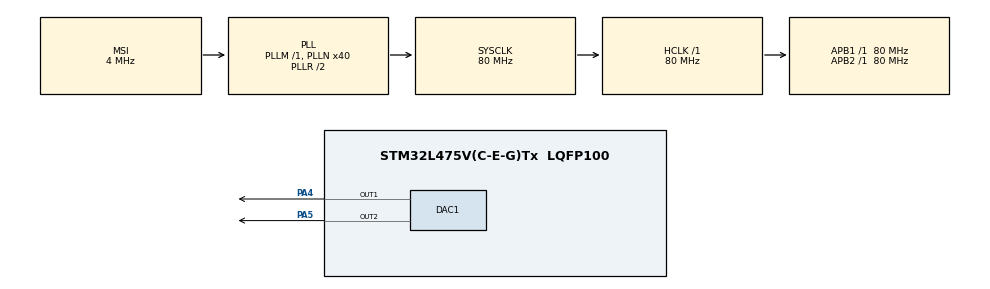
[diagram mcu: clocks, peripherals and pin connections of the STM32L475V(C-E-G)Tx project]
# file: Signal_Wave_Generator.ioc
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DAC1.DAC_Channel-DAC_OUT2=DAC_CHANNEL_2
Mcu.Family=STM32L4
Mcu.Name=STM32L475V(C-E-G)Tx
Mcu.Package=LQFP100
NVIC.PriorityGroup=NVIC_PRIORITYGROUP_4
PA13\ (JTMS-SWDIO).Signal=SYS_JTMS-SWDIO
PA4.Signal=COMP_DAC11_group
PA5.Signal=COMP_DAC12_group
PB3\ (JTDO-TRACESWO).Signal=SYS_JTDO-SWO
ProjectManager.HeapSize=0x200
ProjectManager.StackSize=0x400
ProjectManager.TargetToolchain=STM32CubeIDE
RCC.ADCFreq_Value=48000000
RCC.AHBFreq_Value=80000000
RCC.APB1Freq_Value=80000000
RCC.APB1TimFreq_Value=80000000
RCC.APB2Freq_Value=80000000
RCC.APB2TimFreq_Value=80000000
RCC.CortexFreq_Value=80000000
RCC.HCLKFreq_Value=80000000
RCC.HSE_VALUE=8000000
RCC.HSI_VALUE=16000000
RCC.MSI_VALUE=4000000
RCC.PLLN=40
RCC.PLLSAI1N=24
RCC.SYSCLKFreq_VALUE=80000000
RCC.SYSCLKSource=RCC_SYSCLKSOURCE_PLLCLK
RCC.USBFreq_Value=48000000
RCC.VCOOutputFreq_Value=160000000
SH.COMP_DAC11_group.0=DAC1_OUT1,DAC_OUT1
SH.COMP_DAC12_group.0=DAC1_OUT2,DAC_OUT2
board=B-L475E-IOT01A1

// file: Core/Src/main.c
/* USER CODE BEGIN Header */
/**
  ******************************************************************************
  * @file           : main.c
  * @brief          : Main program body
  ******************************************************************************
  * @attention
  *
  * <h2><center>&copy; Copyright (c) 2021 STMicroelectronics.
  * All rights reserved.</center></h2>
  *
  * This software component is licensed by ST under BSD 3-Clause license,
  * the "License"; You may not use this file except in compliance with the
  * License. You may obtain a copy of the License at:
  *                        opensource.org/licenses/BSD-3-Clause
  *
  ******************************************************************************
  */
/* USER CODE END Header */
#include "main.h"

/* USER CODE BEGIN Includes */
#define ARM_MATH_CM4
#include "arm_math.h"

/* USER CODE END Includes */

/* USER CODE BEGIN PD */
#define M_PI 3.14159265358979323846
/* USER CODE END PD */

DAC_HandleTypeDef hdac1;

void SystemClock_Config(void);
static void MX_GPIO_Init(void);
static void MX_DAC1_Init(void);

int main(void)
{

  /* MCU Configuration--------------------------------------------------------*/

  /* Reset of all peripherals, Initializes the Flash interface and the Systick. */
  HAL_Init();

  /* Configure the system clock */
  SystemClock_Config();

  /* Initialize all configured peripherals */
  MX_GPIO_Init();
  MX_DAC1_Init();
  /* USER CODE BEGIN 2 */

  uint32_t SAW[16] = {0,256, 512, 768,1024,1280,1536,1792,2048,2308,2560,2816,3072,3328,3584,3840};
  uint32_t Triangle[16] = {0,500,1000,1500,2000,2500,3000,3500,4000,3500,3000,2500,2000,1500,1000,500};

/*      float32_t time_rad[100] = {};
      for (uint8_t i = 0; i < 100; i++)
        {
          time_rad[i] = (2 * i * M_PI) / (float)100;
        }
      uint32_t  sine_wave[100] =  {};

      for (uint8_t i = 0; i < 100; i++)
           {
            sine_wave[i] =fabs(4094*arm_sin_f32(time_rad[i]));
           }*/

  uint8_t i=0, j=0;
  uint32_t saw_out,trig_out;
  uint32_t sin_out;
  HAL_DAC_Start(&hdac1, DAC1_CHANNEL_1);
  HAL_DAC_Start(&hdac1, DAC1_CHANNEL_2);

  /* USER CODE END 2 */

  /* Infinite loop */
  while (1)
  {

    /* USER CODE BEGIN 3 */
	  saw_out = SAW[j];
	  trig_out = Triangle[j++];
	 // sin_out = sine_wave[i++];

	  //HAL_DAC_SetValue(&hdac1, DAC1_CHANNEL_1,DAC_ALIGN_12B_R,saw_out);
	  DAC1->DHR12R1 = saw_out;
	  DAC1-> DHR12R2 = trig_out;
	  if(j == 16) { j = 0; }
	  	  	  	  	  	  	  	  	  // frequency = 1/timePeriod = 1/(samplesPerPeriod*sampleDelay)
	  HAL_Delay(0.9615);					//sampleDelay = 1/(samplePerPeriod*freq)
	  	  	  	  	  	  	  	  	  	  // delay  =  1/(16*65) = 0.9615 ms;
	  //DAC1->DHR12R1 = sin_out;
	  //if(i == 100) {i=0; }
	  //HAL_Delay(0.01538);
  }
  /* USER CODE END 3 */
}

void SystemClock_Config(void)
{
  RCC_OscInitTypeDef RCC_OscInitStruct = {0};
  RCC_ClkInitTypeDef RCC_ClkInitStruct = {0};

  /** Configure the main internal regulator output voltage
  */
  if (HAL_PWREx_ControlVoltageScaling(PWR_REGULATOR_VOLTAGE_SCALE1) != HAL_OK)
  {
    Error_Handler();
  }
  /** Initializes the RCC Oscillators according to the specified parameters
  * in the RCC_OscInitTypeDef structure.
  */
  RCC_OscInitStruct.OscillatorType = RCC_OSCILLATORTYPE_MSI;
  RCC_OscInitStruct.MSIState = RCC_MSI_ON;
  RCC_OscInitStruct.MSICalibrationValue = 0;
  RCC_OscInitStruct.MSIClockRange = RCC_MSIRANGE_6;
  RCC_OscInitStruct.PLL.PLLState = RCC_PLL_ON;
  RCC_OscInitStruct.PLL.PLLSource = RCC_PLLSOURCE_MSI;
  RCC_OscInitStruct.PLL.PLLM = 1;
  RCC_OscInitStruct.PLL.PLLN = 40;
  RCC_OscInitStruct.PLL.PLLP = RCC_PLLP_DIV7;
  RCC_OscInitStruct.PLL.PLLQ = RCC_PLLQ_DIV2;
  RCC_OscInitStruct.PLL.PLLR = RCC_PLLR_DIV2;
  if (HAL_RCC_OscConfig(&RCC_OscInitStruct) != HAL_OK)
  {
    Error_Handler();
  }
  /** Initializes the CPU, AHB and APB buses clocks
  */
  RCC_ClkInitStruct.ClockType = RCC_CLOCKTYPE_HCLK|RCC_CLOCKTYPE_SYSCLK
                              |RCC_CLOCKTYPE_PCLK1|RCC_CLOCKTYPE_PCLK2;
  RCC_ClkInitStruct.SYSCLKSource = RCC_SYSCLKSOURCE_PLLCLK;
  RCC_ClkInitStruct.AHBCLKDivider = RCC_SYSCLK_DIV1;
  RCC_ClkInitStruct.APB1CLKDivider = RCC_HCLK_DIV1;
  RCC_ClkInitStruct.APB2CLKDivider = RCC_HCLK_DIV1;

  if (HAL_RCC_ClockConfig(&RCC_ClkInitStruct, FLASH_LATENCY_4) != HAL_OK)
  {
    Error_Handler();
  }
}

static void MX_DAC1_Init(void)
{

  DAC_ChannelConfTypeDef sConfig = {0};

  /** DAC Initialization
  */
  hdac1.Instance = DAC1;
  if (HAL_DAC_Init(&hdac1) != HAL_OK)
  {
    Error_Handler();
  }
  /** DAC channel OUT1 config
  */
  sConfig.DAC_SampleAndHold = DAC_SAMPLEANDHOLD_DISABLE;
  sConfig.DAC_Trigger = DAC_TRIGGER_NONE;
  sConfig.DAC_OutputBuffer = DAC_OUTPUTBUFFER_ENABLE;
  sConfig.DAC_ConnectOnChipPeripheral = DAC_CHIPCONNECT_DISABLE;
  sConfig.DAC_UserTrimming = DAC_TRIMMING_FACTORY;
  if (HAL_DAC_ConfigChannel(&hdac1, &sConfig, DAC_CHANNEL_1) != HAL_OK)
  {
    Error_Handler();
  }
  /** DAC channel OUT2 config
  */
  if (HAL_DAC_ConfigChannel(&hdac1, &sConfig, DAC_CHANNEL_2) != HAL_OK)
  {
    Error_Handler();
  }

}

static void MX_GPIO_Init(void)
{

  /* GPIO Ports Clock Enable */
  __HAL_RCC_GPIOA_CLK_ENABLE();
  __HAL_RCC_GPIOB_CLK_ENABLE();

}

void Error_Handler(void)
{
  __disable_irq();
  while (1)
  {
  }
}

/************************ (C) COPYRIGHT STMicroelectronics *****END OF FILE****/
